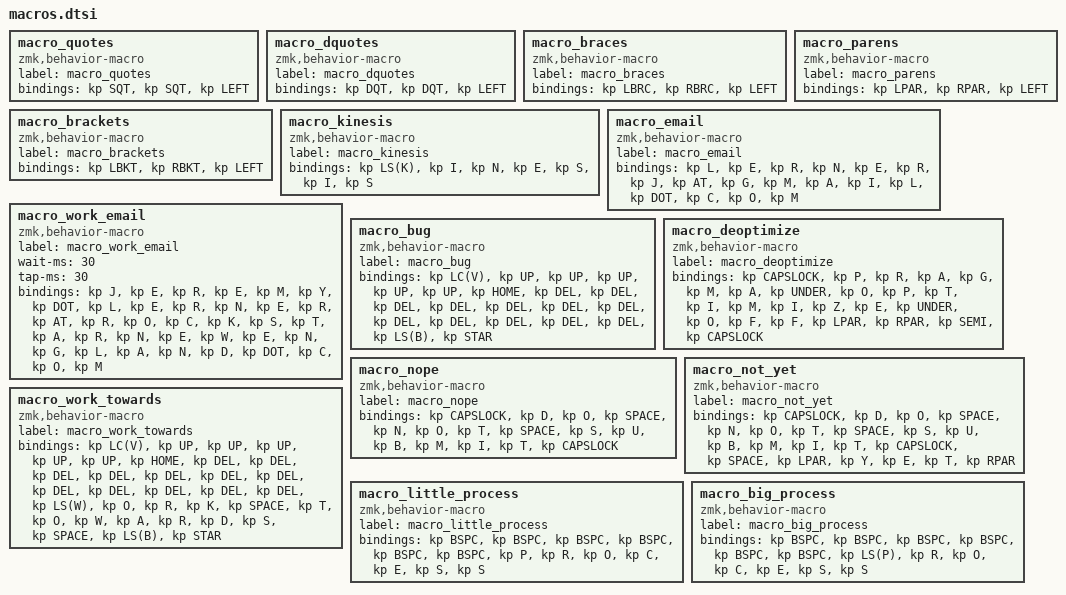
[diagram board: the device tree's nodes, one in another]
macro_quotes: macro_quotes{
	compatible = "zmk,behavior-macro";
	label = "macro_quotes";
	#binding-cells = <0>;
	bindings = <&kp SQT>, <&kp SQT>, <&kp LEFT>;
};
macro_dquotes: macro_dquotes{
	compatible = "zmk,behavior-macro";
	label = "macro_dquotes";
	#binding-cells = <0>;
	bindings = <&kp DQT>, <&kp DQT>, <&kp LEFT>;
};
macro_braces: macro_braces{
	compatible = "zmk,behavior-macro";
	label = "macro_braces";
	#binding-cells = <0>;
	bindings = <&kp LBRC>, <&kp RBRC>, <&kp LEFT>;
};
macro_parens: macro_parens{
	compatible = "zmk,behavior-macro";
	label = "macro_parens";
	#binding-cells = <0>;
	bindings = <&kp LPAR>, <&kp RPAR>, <&kp LEFT>;
};
macro_brackets: macro_brackets{
	compatible = "zmk,behavior-macro";
	label = "macro_brackets";
	#binding-cells = <0>;
	bindings = <&kp LBKT>, <&kp RBKT>, <&kp LEFT>;
};
macro_kinesis: macro_kinesis{
	compatible = "zmk,behavior-macro";
	label = "macro_kinesis";
	#binding-cells = <0>;
	bindings = <&kp LS(K)>, <&kp I>, <&kp N>, <&kp E>, <&kp S>, <&kp I>, <&kp S>;
};
macro_email: macro_email{
	compatible = "zmk,behavior-macro";
	label = "macro_email";
	#binding-cells = <0>;
	bindings = <&kp L>, <&kp E>, <&kp R>, <&kp N>, <&kp E>, <&kp R>, <&kp J>, 
		<&kp AT>, <&kp G>, <&kp M>, <&kp A>, <&kp I>, <&kp L>, 
		<&kp DOT>, <&kp C>, <&kp O>, <&kp M>;
};
macro_work_email: macro_work_email{
	compatible = "zmk,behavior-macro";
	label = "macro_work_email";
	#binding-cells = <0>;
	wait-ms = <30>;
	tap-ms = <30>;
	bindings = <&kp J>, <&kp E>, <&kp R>, <&kp E>, <&kp M>, <&kp Y>, 
		<&kp DOT>, <&kp L>, <&kp E>, <&kp R>, <&kp N>, <&kp E>, <&kp R>,
		<&kp AT>, <&kp R>, <&kp O>, <&kp C>, <&kp K>, <&kp S>, <&kp T>, <&kp A>, <&kp R>,
		<&kp N>, <&kp E>, <&kp W>, <&kp E>, <&kp N>, <&kp G>, <&kp L>, <&kp A>, <&kp N>, <&kp D>,
		<&kp DOT>, <&kp C>, <&kp O>, <&kp M>;
};
macro_bug: macro_bug{
	compatible = "zmk,behavior-macro";
	label = "macro_bug";
	#binding-cells = <0>;
	bindings = <&kp LC(V)>, <&kp UP>, <&kp UP>, <&kp UP>, <&kp UP>, <&kp UP>, <&kp HOME>, 
		<&kp DEL>, <&kp DEL>, <&kp DEL>, <&kp DEL>, <&kp DEL>, <&kp DEL>, <&kp DEL>, <&kp DEL>, <&kp DEL>, <&kp DEL>, <&kp DEL>, <&kp DEL>, 
		<&kp LS(B)>, <&kp STAR>;
};
macro_deoptimize: macro_deoptimize{
	compatible = "zmk,behavior-macro";
	label = "macro_deoptimize";
	#binding-cells = <0>;
	bindings = <&kp CAPSLOCK>, 
		<&kp P>, <&kp R>, <&kp A>, <&kp G>, <&kp M>, <&kp A>, <&kp UNDER>,
		<&kp O>, <&kp P>, <&kp T>, <&kp I>, <&kp M>, <&kp I>, <&kp Z>, <&kp E>, <&kp UNDER>, 
		<&kp O>, <&kp F>, <&kp F>, <&kp LPAR>, <&kp RPAR>, <&kp SEMI>, 
		<&kp CAPSLOCK>;
};
macro_nope: macro_nope{
	compatible = "zmk,behavior-macro";
	label = "macro_nope";
	#binding-cells = <0>;
	bindings = <&kp CAPSLOCK>, 
		<&kp D>, <&kp O>, <&kp SPACE>, <&kp N>, <&kp O>, <&kp T>, <&kp SPACE>, <&kp S>, <&kp U>, <&kp B>, <&kp M>, <&kp I>, <&kp T>,
		<&kp CAPSLOCK>;
};
macro_not_yet: macro_not_yet{
	compatible = "zmk,behavior-macro";
	label = "macro_not_yet";
	#binding-cells = <0>;
	bindings = <&kp CAPSLOCK>, 
		<&kp D>, <&kp O>, <&kp SPACE>, <&kp N>, <&kp O>, <&kp T>, <&kp SPACE>, <&kp S>, <&kp U>, <&kp B>, <&kp M>, <&kp I>, <&kp T>,
		<&kp CAPSLOCK>,
		<&kp SPACE>, <&kp LPAR>, <&kp Y>, <&kp E>, <&kp T>, <&kp RPAR>;
};
macro_work_towards: macro_work_towards{
	compatible = "zmk,behavior-macro";
	label = "macro_work_towards";
	#binding-cells = <0>;
	bindings = <&kp LC(V)>, <&kp UP>, <&kp UP>, <&kp UP>, <&kp UP>, <&kp UP>, <&kp HOME>, 
		<&kp DEL>, <&kp DEL>, <&kp DEL>, <&kp DEL>, <&kp DEL>, <&kp DEL>, <&kp DEL>, <&kp DEL>, <&kp DEL>, <&kp DEL>, <&kp DEL>, <&kp DEL>, 
		<&kp LS(W)>, <&kp O>, <&kp R>, <&kp K>, <&kp SPACE>, <&kp T>, <&kp O>, <&kp W>, <&kp A>, <&kp R>, <&kp D>, <&kp S>, <&kp SPACE>, <&kp LS(B)>, <&kp STAR>;
};
macro_little_process: macro_little_process{
	compatible = "zmk,behavior-macro";
	label = "macro_little_process";
	#binding-cells = <0>;
	bindings = <&kp BSPC>, <&kp BSPC>, <&kp BSPC>, <&kp BSPC>, <&kp BSPC>, <&kp BSPC>, 
		<&kp P>, <&kp R>, <&kp O>, <&kp C>, <&kp E>, <&kp S>, <&kp S>;
};
macro_big_process: macro_big_process{
	compatible = "zmk,behavior-macro";
	label = "macro_big_process";
	#binding-cells = <0>;
	bindings = <&kp BSPC>, <&kp BSPC>, <&kp BSPC>, <&kp BSPC>, <&kp BSPC>, <&kp BSPC>, 
		<&kp LS(P)>, <&kp R>, <&kp O>, <&kp C>, <&kp E>, <&kp S>, <&kp S>;
};


